VERSION ""

NS_ :

BS_:
BU_: VEHICLE
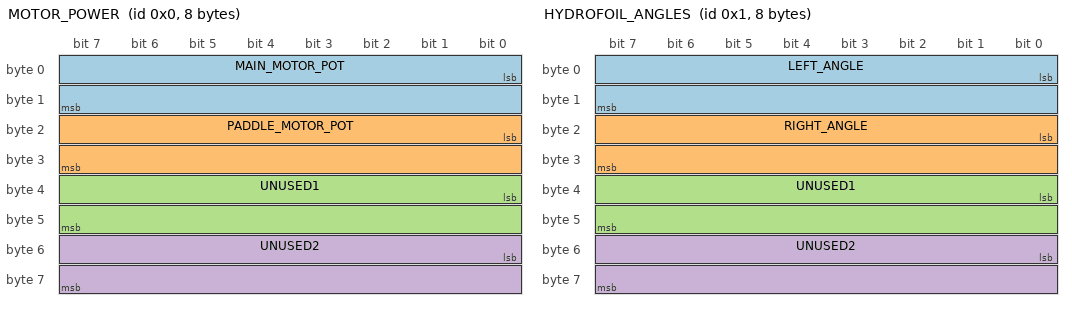
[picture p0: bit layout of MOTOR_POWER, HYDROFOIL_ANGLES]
BO_ 0 MOTOR_POWER: 8 VEHICLE
   SG_ MAIN_MOTOR_POT : 0|16@1- (0.1,0) [-100|100] "%" Vector__XXX
   SG_ PADDLE_MOTOR_POT : 16|16@1- (0.1,0) [-100|100] "%" Vector__XXX
   SG_ UNUSED1 : 32|16@1- (1,0) [0|1] "" Vector__XXX
   SG_ UNUSED2 : 48|16@1- (1,0) [0|1] "" Vector__XXX

BO_ 1 HYDROFOIL_ANGLES: 8 VEHICLE
   SG_ LEFT_ANGLE : 0|16@1- (0.01,0) [-10|10] "" Vector__XXX
   SG_ RIGHT_ANGLE : 16|16@1- (0.01,0) [-10|10] "" Vector__XXX
   SG_ UNUSED1 : 32|16@1- (1,0) [0|1] "" Vector__XXX
   SG_ UNUSED2 : 48|16@1- (1,0) [0|1] "" Vector__XXX

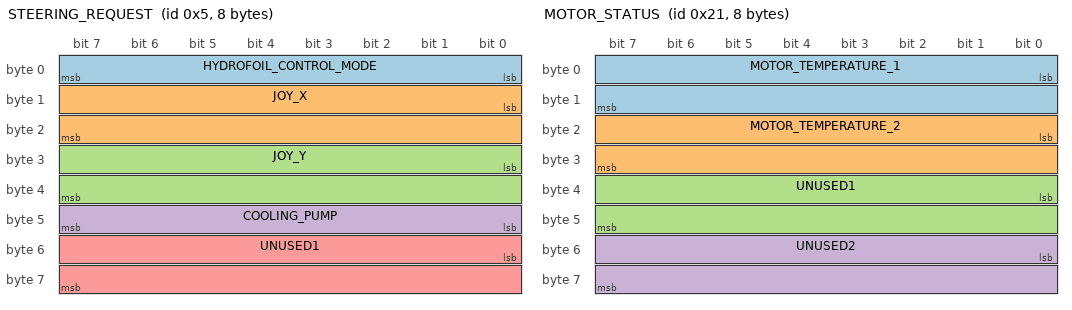
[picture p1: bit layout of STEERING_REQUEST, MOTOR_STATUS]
BO_ 5 STEERING_REQUEST: 8 VEHICLE
   SG_ HYDROFOIL_CONTROL_MODE : 0|8@1+ (1,0) [0|2] "" Vector__XXX
   SG_ JOY_X : 8|16@1+ (1,0) [0|4000] "" Vector__XXX
   SG_ JOY_Y : 24|16@1+ (1,0) [0|4000] "" Vector__XXX
   SG_ COOLING_PUMP : 40|8@1+ (1,0) [0|2] "" Vector__XXX
   SG_ UNUSED1 : 48|16@1- (1,0) [0|1] "" Vector__XXX

BO_ 33 MOTOR_STATUS: 8 VEHICLE
   SG_ MOTOR_TEMPERATURE_1 : 0|16@1+ (1,0) [0|200] "C" Vector__XXX
   SG_ MOTOR_TEMPERATURE_2 : 16|16@1+ (1,0) [0|200] "C" Vector__XXX
   SG_ UNUSED1 : 32|16@1- (1,0) [0|1] "" Vector__XXX
   SG_ UNUSED2 : 48|16@1- (1,0) [0|1] "" Vector__XXX

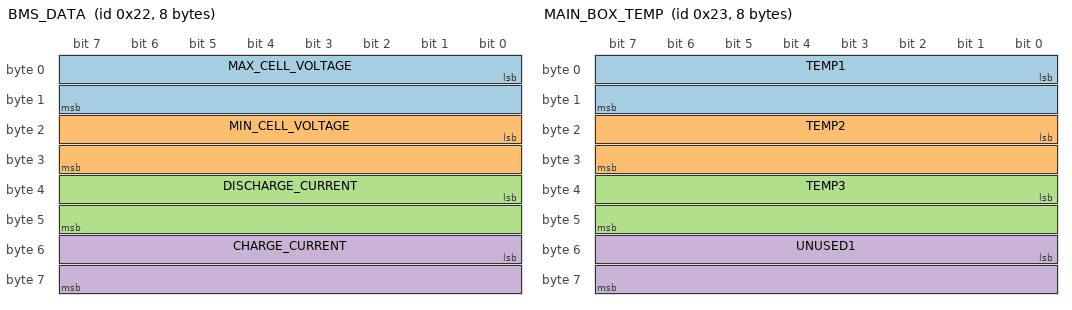
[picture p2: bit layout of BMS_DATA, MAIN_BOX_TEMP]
BO_ 34 BMS_DATA: 8 VEHICLE
   SG_ MAX_CELL_VOLTAGE : 0|16@1+ (0.0001,0) [0|5] "V" Vector__XXX
   SG_ MIN_CELL_VOLTAGE : 16|16@1+ (0.0001,0) [0|5] "V" Vector__XXX
   SG_ DISCHARGE_CURRENT : 32|16@1+ (0.01,0) [-20|500] "A" Vector__XXX
   SG_ CHARGE_CURRENT : 48|16@1+ (0.01,0) [0|100] "A" Vector__XXX

BO_ 35 MAIN_BOX_TEMP: 8 VEHICLE
   SG_ TEMP1 : 0|16@1+ (0.01,0) [0|200] "C" Vector__XXX
   SG_ TEMP2 : 16|16@1+ (0.01,0) [0|200] "C" Vector__XXX
   SG_ TEMP3 : 32|16@1+ (0.01,0) [0|200] "C" Vector__XXX
   SG_ UNUSED1 : 48|16@1- (1,0) [0|1] "" Vector__XXX

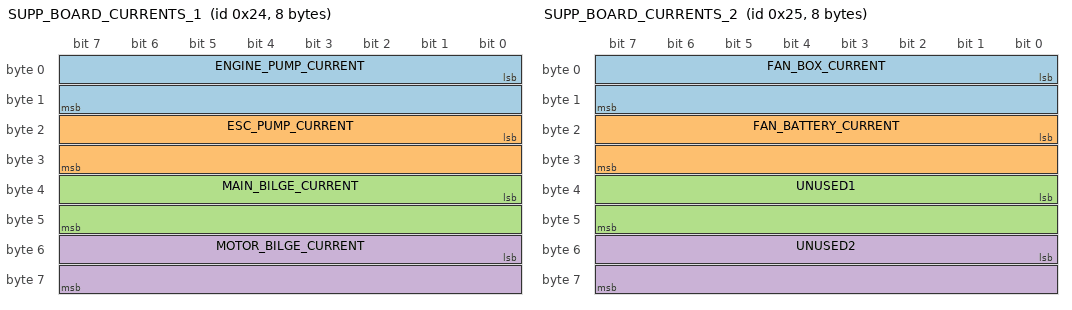
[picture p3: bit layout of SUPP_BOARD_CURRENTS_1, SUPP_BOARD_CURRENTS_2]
BO_ 36 SUPP_BOARD_CURRENTS_1: 8 VEHICLE
   SG_ ENGINE_PUMP_CURRENT : 0|16@1+ (0.001,0) [0|5] "A" Vector__XXX
   SG_ ESC_PUMP_CURRENT : 16|16@1+ (0.001,0) [0|5] "A" Vector__XXX
   SG_ MAIN_BILGE_CURRENT : 32|16@1+ (0.001,0) [0|5] "A" Vector__XXX
   SG_ MOTOR_BILGE_CURRENT : 48|16@1+ (0.001,0) [0|5] "A" Vector__XXX

BO_ 37 SUPP_BOARD_CURRENTS_2: 8 VEHICLE
   SG_ FAN_BOX_CURRENT : 0|16@1+ (0.001,0) [0|5] "A" Vector__XXX
   SG_ FAN_BATTERY_CURRENT : 16|16@1+ (0.001,0) [0|5] "A" Vector__XXX
   SG_ UNUSED1 : 32|16@1- (1,0) [0|1] "" Vector__XXX
   SG_ UNUSED2 : 48|16@1- (1,0) [0|1] "" Vector__XXX

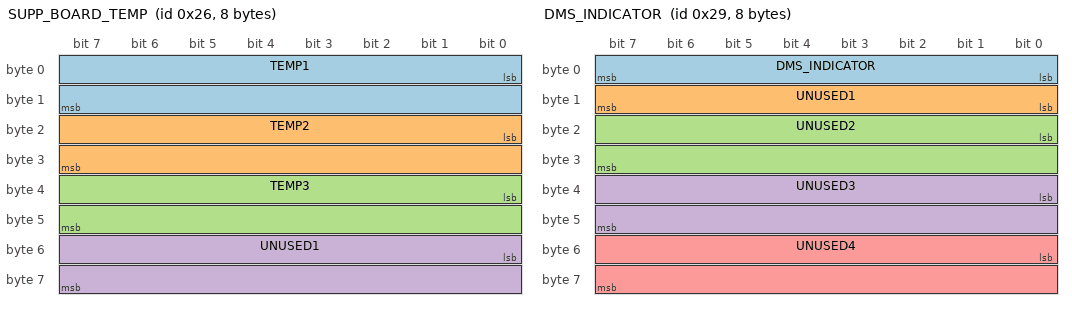
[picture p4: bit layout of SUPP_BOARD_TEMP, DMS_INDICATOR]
BO_ 38 SUPP_BOARD_TEMP: 8 VEHICLE
   SG_ TEMP1 : 0|16@1+ (1,0) [0|200] "C" Vector__XXX
   SG_ TEMP2 : 16|16@1+ (1,0) [0|200] "C" Vector__XXX
   SG_ TEMP3 : 32|16@1+ (1,0) [0|200] "C" Vector__XXX
   SG_ UNUSED1 : 48|16@1- (1,0) [0|1] "" Vector__XXX

BO_ 39 PV_VOLTAGE: 8 VEHICLE
   SG_ PV_SERIES_IDX : 0|8@1+ (1,0) [0|7] "" Vector__XXX
   SG_ VOLTAGE : 8|32@1+ (1,0) [0|60000] "mV" Vector__XXX

BO_ 40 PV_CURRENT: 5 VEHICLE
   SG_ PV_SERIES_IDX : 0|8@1+ (1,0) [0|7] "" Vector__XXX
   SG_ CURRENT : 8|32@1- (1,0) [-4000|6000] "mA" Vector__XXX

BO_ 41 DMS_INDICATOR: 8 VEHICLE
   SG_ DMS_INDICATOR : 0|8@1+ (1,0) [0|1] "" Vector__XXX
   SG_ UNUSED1 : 8|8@1- (1,0) [0|1] "" Vector__XXX
   SG_ UNUSED2 : 16|16@1- (1,0) [0|1] "" Vector__XXX
   SG_ UNUSED3 : 32|16@1- (1,0) [0|1] "" Vector__XXX
   SG_ UNUSED4 : 48|16@1- (1,0) [0|1] "" Vector__XXX

VAL_ 5 HYDROFOIL_CONTROL_MODE 0 "AUTOMATIC" 1 "MANUAL_LINEAR_SPLINE_MIXER" 2 "MANUAL_ROLL_PID";
VAL_ 5 COOLING_PUMP 0 "OFF" 1 "ON" 2 "AUTO";
VAL_ 41 DMS_INDICATOR 0 "UNPLUGGED" 1 "PLUGGED";
